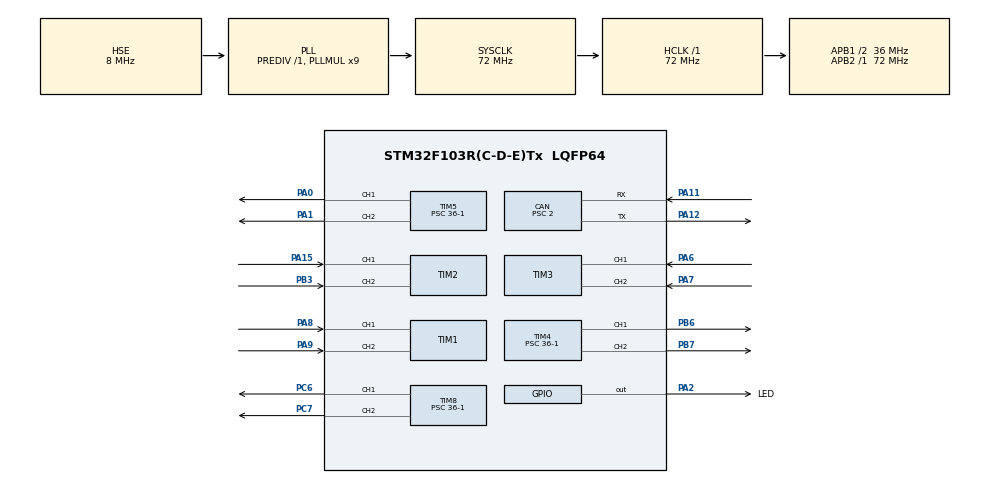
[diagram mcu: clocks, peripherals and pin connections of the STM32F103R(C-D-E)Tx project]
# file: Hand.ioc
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CAN.BS1=CAN_BS1_9TQ
CAN.BS2=CAN_BS2_8TQ
CAN.CalculateBaudRate=1000000
CAN.CalculateTimeBit=1000
CAN.CalculateTimeQuantum=55.55555555555556
CAN.Prescaler=2
Mcu.Family=STM32F1
Mcu.Name=STM32F103R(C-D-E)Tx
Mcu.Package=LQFP64
NVIC.PriorityGroup=NVIC_PRIORITYGROUP_4
NVIC.TIM6_IRQn=true\:0\:0\:false\:false\:true\:true\:true\:true
NVIC.USB_LP_CAN1_RX0_IRQn=true\:1\:0\:true\:false\:true\:true\:true\:true
PA0-WKUP.Signal=S_TIM5_CH1
PA1.Signal=S_TIM5_CH2
PA11.Mode=CAN_Activate
PA11.Signal=CAN_RX
PA12.Mode=CAN_Activate
PA12.Signal=CAN_TX
PA13.Mode=Serial_Wire
PA13.Signal=SYS_JTMS-SWDIO
PA14.Mode=Serial_Wire
PA14.Signal=SYS_JTCK-SWCLK
PA15.Signal=S_TIM2_CH1_ETR
PA2.GPIO_Label=LED
PA2.GPIO_Speed=GPIO_SPEED_FREQ_HIGH
PA2.PinState=GPIO_PIN_RESET
PA2.Signal=GPIO_Output
PA6.Signal=S_TIM3_CH1
PA7.Signal=S_TIM3_CH2
PA8.Signal=S_TIM1_CH1
PA9.Signal=S_TIM1_CH2
PB3.Signal=S_TIM2_CH2
PB6.Signal=S_TIM4_CH1
PB7.Signal=S_TIM4_CH2
PC6.Signal=S_TIM8_CH1
PC7.Signal=S_TIM8_CH2
PD0-OSC_IN.Mode=HSE-External-Oscillator
PD0-OSC_IN.Signal=RCC_OSC_IN
PD1-OSC_OUT.Mode=HSE-External-Oscillator
PD1-OSC_OUT.Signal=RCC_OSC_OUT
ProjectManager.HeapSize=0x200
ProjectManager.StackSize=0x400
ProjectManager.TargetToolchain=CMake
RCC.AHBFreq_Value=72000000
RCC.APB1CLKDivider=RCC_HCLK_DIV2
RCC.APB1Freq_Value=36000000
RCC.APB1TimFreq_Value=72000000
RCC.APB2Freq_Value=72000000
RCC.APB2TimFreq_Value=72000000
RCC.HCLKFreq_Value=72000000
RCC.PLLMUL=RCC_PLL_MUL9
RCC.PLLSourceVirtual=RCC_PLLSOURCE_HSE
RCC.SYSCLKFreq_VALUE=72000000
RCC.SYSCLKSource=RCC_SYSCLKSOURCE_PLLCLK
RCC.USBFreq_Value=72000000
SH.S_TIM1_CH1.0=TIM1_CH1,Encoder_Interface
SH.S_TIM1_CH2.0=TIM1_CH2,Encoder_Interface
SH.S_TIM2_CH1_ETR.0=TIM2_CH1,Encoder_Interface
SH.S_TIM2_CH2.0=TIM2_CH2,Encoder_Interface
SH.S_TIM3_CH1.0=TIM3_CH1,Encoder_Interface
SH.S_TIM3_CH2.0=TIM3_CH2,Encoder_Interface
SH.S_TIM4_CH1.0=TIM4_CH1,PWM Generation1 CH1
SH.S_TIM4_CH2.0=TIM4_CH2,PWM Generation2 CH2
SH.S_TIM5_CH1.0=TIM5_CH1,PWM Generation1 CH1
SH.S_TIM5_CH2.0=TIM5_CH2,PWM Generation2 CH2
SH.S_TIM8_CH1.0=TIM8_CH1,PWM Generation1 CH1
SH.S_TIM8_CH2.0=TIM8_CH2,PWM Generation2 CH2
TIM1.AutoReloadPreload=TIM_AUTORELOAD_PRELOAD_ENABLE
TIM1.EncoderMode=TIM_ENCODERMODE_TI12
TIM1.IC1Filter=0
TIM1.IC2Filter=6
TIM2.AutoReloadPreload=TIM_AUTORELOAD_PRELOAD_ENABLE
TIM2.EncoderMode=TIM_ENCODERMODE_TI12
TIM2.IC1Filter=0
TIM2.IC2Filter=6
TIM3.AutoReloadPreload=TIM_AUTORELOAD_PRELOAD_ENABLE
TIM3.EncoderMode=TIM_ENCODERMODE_TI12
TIM3.IC1Filter=0
TIM3.IC2Filter=6
TIM4.AutoReloadPreload=TIM_AUTORELOAD_PRELOAD_ENABLE
TIM4.Channel-PWM\ Generation1\ CH1=TIM_CHANNEL_1
TIM4.Channel-PWM\ Generation2\ CH2=TIM_CHANNEL_2
TIM4.Period=100-1
TIM4.Prescaler=36-1
TIM5.AutoReloadPreload=TIM_AUTORELOAD_PRELOAD_ENABLE
TIM5.Channel-PWM\ Generation1\ CH1=TIM_CHANNEL_1
TIM5.Channel-PWM\ Generation2\ CH2=TIM_CHANNEL_2
TIM5.Period=100-1
TIM5.Prescaler=36-1
TIM6.AutoReloadPreload=TIM_AUTORELOAD_PRELOAD_ENABLE
TIM6.Period=100-1
TIM6.Prescaler=7200-1
TIM8.AutoReloadPreload=TIM_AUTORELOAD_PRELOAD_ENABLE
TIM8.Channel-PWM\ Generation1\ CH1=TIM_CHANNEL_1
TIM8.Channel-PWM\ Generation2\ CH2=TIM_CHANNEL_2
TIM8.Period=100-1
TIM8.Prescaler=36-1
VP_TIM4_VS_ClockSourceINT.Mode=Internal
VP_TIM5_VS_ClockSourceINT.Mode=Internal
VP_TIM6_VS_ClockSourceINT.Mode=Enable_Timer
VP_TIM8_VS_ClockSourceINT.Mode=Internal
board=custom

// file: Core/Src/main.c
/* USER CODE BEGIN Header */
/**
  ******************************************************************************
  * @file           : main.c
  * @brief          : Main program body
  ******************************************************************************
  * @attention
  *
  * Copyright (c) 2025 STMicroelectronics.
  * All rights reserved.
  *
  * This software is licensed under terms that can be found in the LICENSE file
  * in the root directory of this software component.
  * If no LICENSE file comes with this software, it is provided AS-IS.
  *
  ******************************************************************************
  */
/* USER CODE END Header */
#include "main.h"
#include "can.h"
#include "tim.h"
#include "gpio.h"

/* USER CODE BEGIN Includes */
#include "bsp_led.h"
#include "bsp_can.h"
#include "bsp_motor.h"
#include "bsp_encoder.h"
#include "pid.h"
#include "timer.h"
/* USER CODE END Includes */

void SystemClock_Config(void);

int main(void)
{

  /* MCU Configuration--------------------------------------------------------*/

  /* Reset of all peripherals, Initializes the Flash interface and the Systick. */
  HAL_Init();

  /* Configure the system clock */
  SystemClock_Config();

  /* Initialize all configured peripherals */
  MX_GPIO_Init();
  MX_CAN_Init();
  MX_TIM1_Init();
  MX_TIM2_Init();
  MX_TIM3_Init();
  MX_TIM4_Init();
  MX_TIM5_Init();
  MX_TIM6_Init();
  MX_TIM8_Init();
  /* USER CODE BEGIN 2 */

  /* Debug初始化 */
  SEGGER_RTT_Init();
  /* 电机初始化 */
  motor_init();
  /* 编码器初始化 */
  encoder_init();
  /* 初始化CAN */
  Can_Handle_t can_handle;
  can_init(&can_handle);
  /* 启动10ms定时 */
  timer_init();

  /* USER CODE END 2 */

  /* Infinite loop */
  /* USER CODE BEGIN WHILE */
  while (1)
  {
    led_toggle();
    HAL_Delay(500);
    /* USER CODE END WHILE */

  }
}

void SystemClock_Config(void)
{
  RCC_OscInitTypeDef RCC_OscInitStruct = {0};
  RCC_ClkInitTypeDef RCC_ClkInitStruct = {0};

  /** Initializes the RCC Oscillators according to the specified parameters
  * in the RCC_OscInitTypeDef structure.
  */
  RCC_OscInitStruct.OscillatorType = RCC_OSCILLATORTYPE_HSE;
  RCC_OscInitStruct.HSEState = RCC_HSE_ON;
  RCC_OscInitStruct.HSEPredivValue = RCC_HSE_PREDIV_DIV1;
  RCC_OscInitStruct.HSIState = RCC_HSI_ON;
  RCC_OscInitStruct.PLL.PLLState = RCC_PLL_ON;
  RCC_OscInitStruct.PLL.PLLSource = RCC_PLLSOURCE_HSE;
  RCC_OscInitStruct.PLL.PLLMUL = RCC_PLL_MUL9;
  if (HAL_RCC_OscConfig(&RCC_OscInitStruct) != HAL_OK)
  {
    Error_Handler();
  }

  /** Initializes the CPU, AHB and APB buses clocks
  */
  RCC_ClkInitStruct.ClockType = RCC_CLOCKTYPE_HCLK|RCC_CLOCKTYPE_SYSCLK
                              |RCC_CLOCKTYPE_PCLK1|RCC_CLOCKTYPE_PCLK2;
  RCC_ClkInitStruct.SYSCLKSource = RCC_SYSCLKSOURCE_PLLCLK;
  RCC_ClkInitStruct.AHBCLKDivider = RCC_SYSCLK_DIV1;
  RCC_ClkInitStruct.APB1CLKDivider = RCC_HCLK_DIV2;
  RCC_ClkInitStruct.APB2CLKDivider = RCC_HCLK_DIV1;

  if (HAL_RCC_ClockConfig(&RCC_ClkInitStruct, FLASH_LATENCY_2) != HAL_OK)
  {
    Error_Handler();
  }
}

void Error_Handler(void)
{
  __disable_irq();
  while (1)
  {
  }
}
